# M3V6 register map
File version: 0.1
Registers are 32-bit, read-write, reset 0x0 unless marked. A register's access mark holds for its fields unless they carry their own. Offsets are from the block's base; [hi:lo] are bit positions; {n}, {i} and the like mark numbered series.

## PD — General Purpose Input_Output Port (PD)
Base 0x400000C0
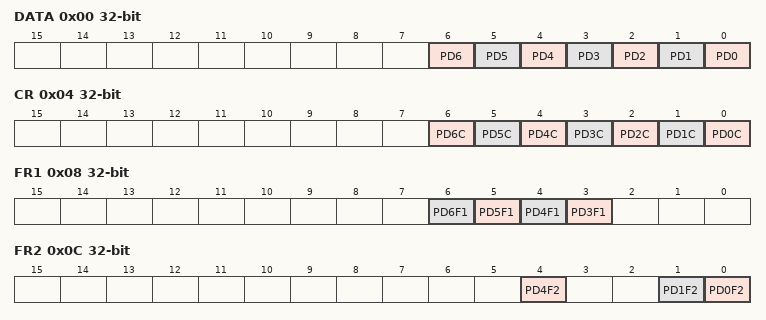
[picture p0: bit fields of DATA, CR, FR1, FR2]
0x00 DATA — PD Data Register
  [n] PD{n} (n=0..6)
0x04 CR — PD Control Register
  [n] PD{n}C (n=0..6)
0x08 FR1 — PD Function Register 1
  [n] PD{n}F1 (n=3..6)
0x0C FR2 — PD Function Register 2
  [4] PD4F2, [1] PD1F2, [0] PD0F2
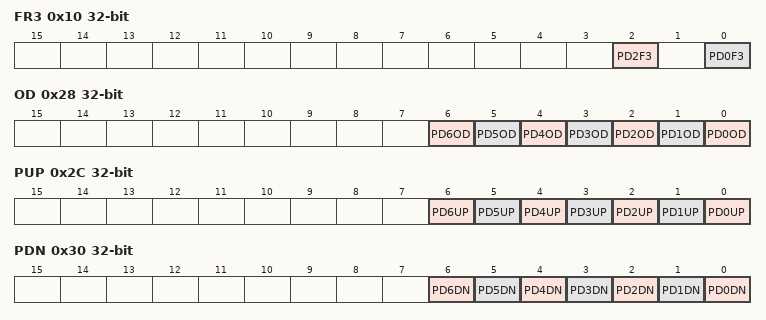
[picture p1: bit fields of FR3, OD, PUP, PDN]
0x10 FR3 — PD Function Register 3
  [2] PD2F3, [0] PD0F3
0x28 OD — PD Open Drain Control Register
  [n] PD{n}OD (n=0..6)
0x2C PUP — PD Pull-Up Control Register
  [n] PD{n}UP (n=0..6)
0x30 PDN — PD Pull-Down Control Register
  [n] PD{n}DN (n=0..6)
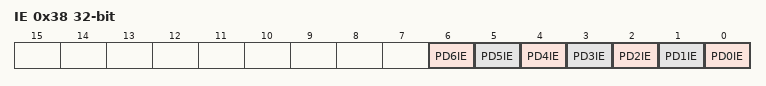
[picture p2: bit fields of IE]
0x38 IE — PD Input Enable Control Register
  [n] PD{n}IE (n=0..6)

## PE — General Purpose Input_Output Port (PE)
Base 0x40000100
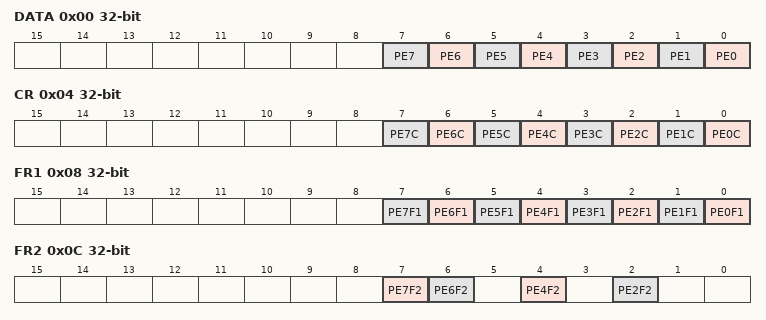
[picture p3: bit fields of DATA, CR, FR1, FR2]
0x00 DATA — PE Data Register
  [n] PE{n} (n=0..7)
0x04 CR — PE Control Register
  [n] PE{n}C (n=0..7)
0x08 FR1 — PE Function Register 1
  [n] PE{n}F1 (n=0..7)
0x0C FR2 — PE Function Register 2
  [7] PE7F2, [6] PE6F2, [4] PE4F2, [2] PE2F2
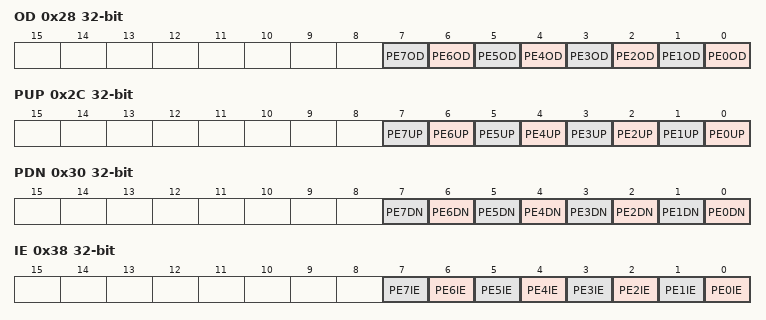
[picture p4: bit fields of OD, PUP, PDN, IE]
0x28 OD — PE Open Drain Control Register
  [n] PE{n}OD (n=0..7)
0x2C PUP — PE Pull-Up Control Register
  [n] PE{n}UP (n=0..7)
0x30 PDN — PE Pull-Down Control Register
  [n] PE{n}DN (n=0..7)
0x38 IE — PE Input Enable Control Register
  [n] PE{n}IE (n=0..7)

## PF — General Purpose Input_Output Port (PF)
Base 0x40000140
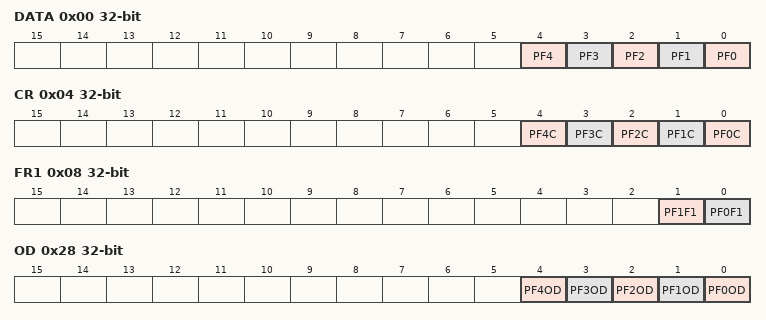
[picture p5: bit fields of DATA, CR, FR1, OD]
0x00 DATA — PF Data Register
  [n] PF{n} (n=0..4)
0x04 CR — PF Control Register
  [n] PF{n}C (n=0..4)
0x08 FR1 — PF Function Register 1
  [1] PF1F1, [0] PF0F1
0x0C FR2 — PF Function Register 2
  [1] PF1F2
0x28 OD — PF Open Drain Control Register
  [n] PF{n}OD (n=0..4)
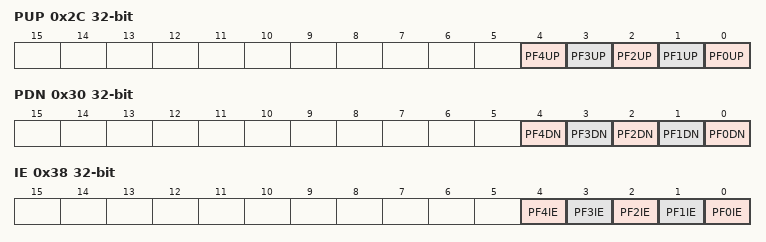
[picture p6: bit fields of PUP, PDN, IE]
0x2C PUP — PF Pull-Up Control Register
  [n] PF{n}UP (n=0..4)
0x30 PDN — PF Pull-Down Control Register
  [n] PF{n}DN (n=0..4)
0x38 IE — PF Input Enable Control Register
  [n] PF{n}IE (n=0..4)

## PG — General Purpose Input_Output Port (PG)
Base 0x40000180
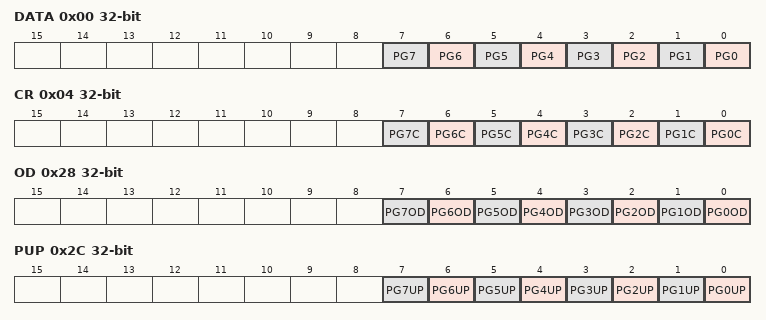
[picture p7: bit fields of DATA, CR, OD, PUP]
0x00 DATA — PG Data Register
  [n] PG{n} (n=0..7)
0x04 CR — PG Control Register
  [n] PG{n}C (n=0..7)
0x28 OD — PG Open Drain Control Register
  [n] PG{n}OD (n=0..7)
0x2C PUP — PG Pull-Up Control Register
  [n] PG{n}UP (n=0..7)
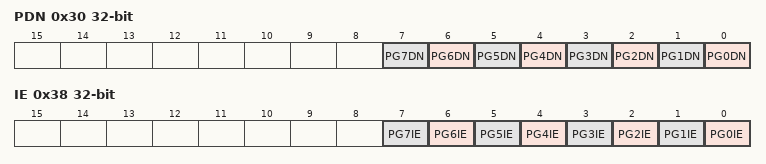
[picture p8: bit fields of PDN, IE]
0x30 PDN — PG Pull-Down Control Register
  [n] PG{n}DN (n=0..7)
0x38 IE — PG Input Enable Control Register
  [n] PG{n}IE (n=0..7)

## PH — General Purpose Input_Output Port (PH)
Base 0x400001C0
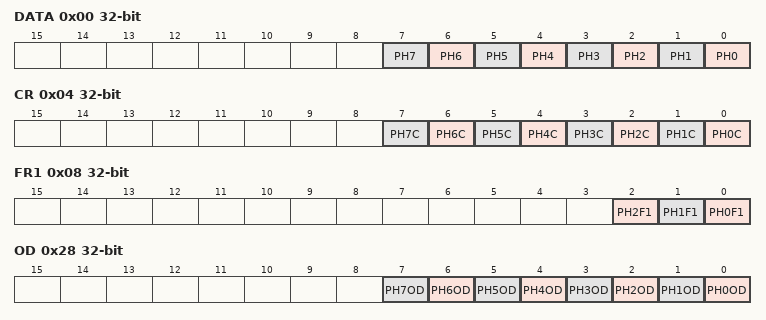
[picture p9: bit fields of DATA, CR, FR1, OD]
0x00 DATA — PH Data Register
  [n] PH{n} (n=0..7)
0x04 CR — PH Control Register
  [n] PH{n}C (n=0..7)
0x08 FR1 — PH Function Register 1
  [2] PH2F1, [1] PH1F1, [0] PH0F1
0x28 OD — PH Open Drain Control Register
  [n] PH{n}OD (n=0..7)
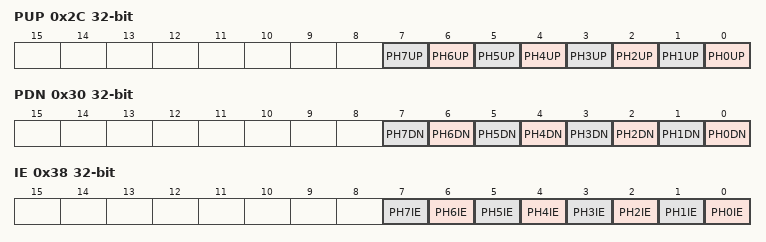
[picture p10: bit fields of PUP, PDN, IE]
0x2C PUP — PH Pull-Up Control Register
  [n] PH{n}UP (n=0..7)
0x30 PDN — PH Pull-Down Control Register
  [n] PH{n}DN (n=0..7)
0x38 IE — PH Input Enable Control Register
  [n] PH{n}IE (n=0..7)

## PI — General Purpose Input_Output Port (PI)
Base 0x40000200
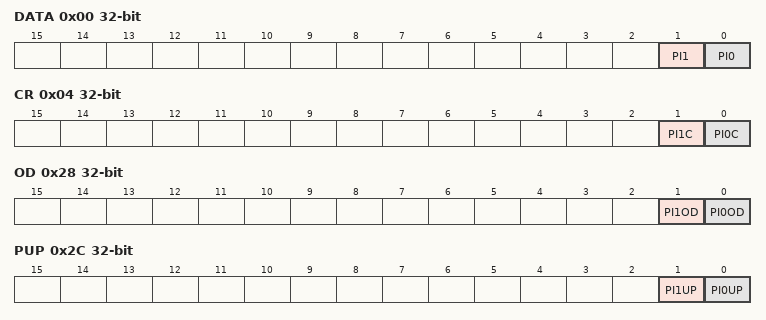
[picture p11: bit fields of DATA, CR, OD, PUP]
0x00 DATA — PI Data Register
  [1] PI1, [0] PI0
0x04 CR — PI Control Register
  [1] PI1C, [0] PI0C
0x28 OD — PI Open Drain Control Register
  [1] PI1OD, [0] PI0OD
0x2C PUP — PI Pull-Up Control Register
  [1] PI1UP, [0] PI0UP
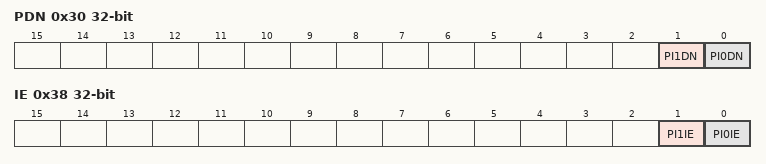
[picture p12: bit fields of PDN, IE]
0x30 PDN — PI Pull-Down Control Register
  [1] PI1DN, [0] PI0DN
0x38 IE — PI Input Enable Control Register
  [1] PI1IE, [0] PI0IE

## PJ — General Purpose Input_Output Port (PJ)
Base 0x40000240
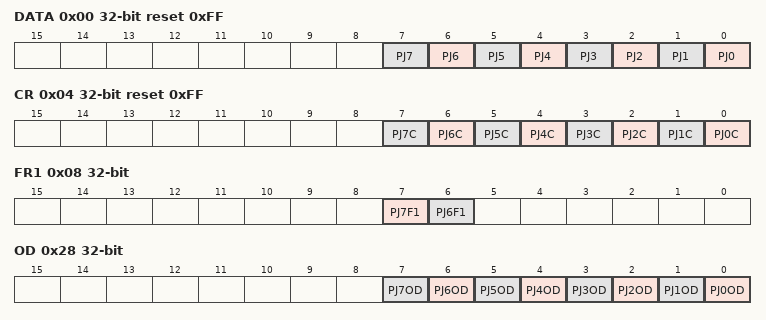
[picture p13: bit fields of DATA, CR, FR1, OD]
0x00 DATA reset 0xFF — PJ Data Register
  [n] PJ{n} (n=0..7)
0x04 CR reset 0xFF — PJ Control Register
  [n] PJ{n}C (n=0..7)
0x08 FR1 — PJ Function Register 1
  [7] PJ7F1, [6] PJ6F1
0x28 OD — PJ Open Drain Control Register
  [n] PJ{n}OD (n=0..7)
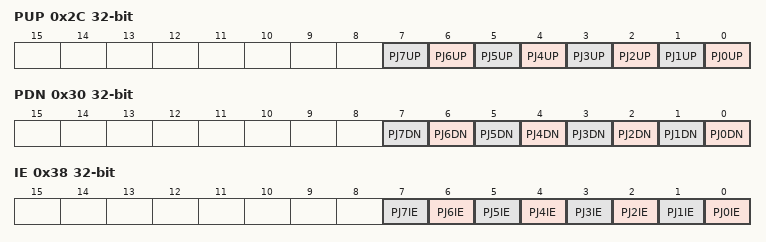
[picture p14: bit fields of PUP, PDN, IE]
0x2C PUP — PJ Pull-Up Control Register
  [n] PJ{n}UP (n=0..7)
0x30 PDN — PJ Pull-Down Control Register
  [n] PJ{n}DN (n=0..7)
0x38 IE — PJ Input Enable Control Register
  [n] PJ{n}IE (n=0..7)

## PL — General Purpose Input_Output Port (PL)
Base 0x400002C0
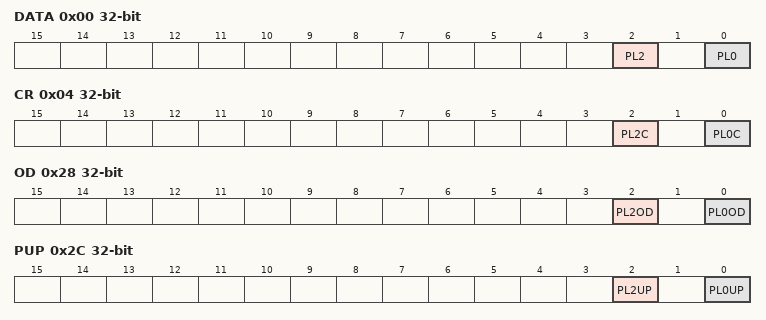
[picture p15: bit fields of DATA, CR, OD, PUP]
0x00 DATA — PL Data Register
  [2] PL2, [0] PL0
0x04 CR — PL Control Register
  [2] PL2C, [0] PL0C
0x08 FR1 — PL Function Register 1
  [2] PL2F1
0x28 OD — PL Open Drain Control Register
  [2] PL2OD, [0] PL0OD
0x2C PUP — PL Pull-Up Control Register
  [2] PL2UP, [0] PL0UP
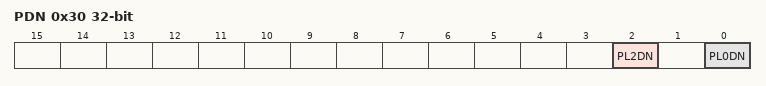
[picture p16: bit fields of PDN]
0x30 PDN — PL Pull-Down Control Register
  [2] PL2DN, [0] PL0DN
0x38 IE — PL Input Enable Control Register
  [2] PL2IE
